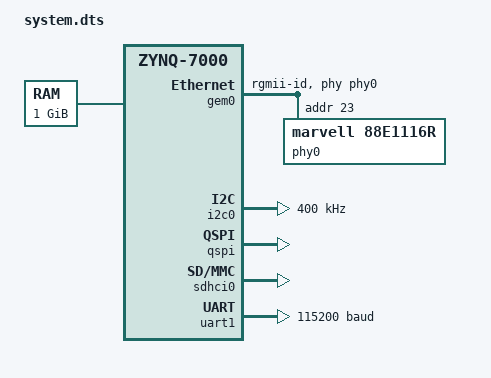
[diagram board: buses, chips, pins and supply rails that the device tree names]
/*
 * CAUTION: This file is automatically generated by Xilinx.
 * Version:
 * Today is: Wed Dec 02 13:59:28 2015
*/


/dts-v1/;
/include/ "zynq-7000.dtsi"
/include/ "pl.dtsi"
/ {
	cpus {
		cpu@0 {
			operating-points = <666666 1000000 333333 1000000>;
		};
	};
	chosen {
		bootargs = "console=ttyPS0,115200 earlyprintk devtmpfs.mount=1";
	};
	aliases {
		ethernet0 = &gem0;
		serial0 = &uart1;
		spi0 = &qspi;
	};
	memory {
		device_type = "memory";
		reg = <0x0 0x40000000>;
	};
};
&gem0 {
	enet-reset = <&gpio0 51 0>;
	local-mac-address = [00 0a 35 00 00 00];
	phy-mode = "rgmii-id";
	status = "okay";
	xlnx,ptp-enet-clock = <0x69f6bcb>;
	phy-handle = <&phy0>;
	phy0: phy@23 {
		compatible = "marvell,88e1116r";
		device_type = "ethernet-phy";
		reg = <0x17>;
	};
};
&gpio0 {
	emio-gpio-width = <64>;
	gpio-mask-high = <0x0>;
	gpio-mask-low = <0x5600>;
};
&i2c0 {
	clock-frequency = <400000>;
	status = "okay";
};
&intc {
	num_cpus = <2>;
	num_interrupts = <96>;
};
&qspi {
	is-dual = <1>;
	num-cs = <1>;
	status = "okay";
};
&sdhci0 {
	status = "okay";
	xlnx,has-cd = <0x0>;
	xlnx,has-power = <0x0>;
	xlnx,has-wp = <0x0>;
};
&uart1 {
	current-speed = <115200>;
	device_type = "serial";
	port-number = <0>;
	status = "okay";
};
&clkc {
	fclk-enable = <0x1>;
	ps-clk-frequency = <33333333>;
};
